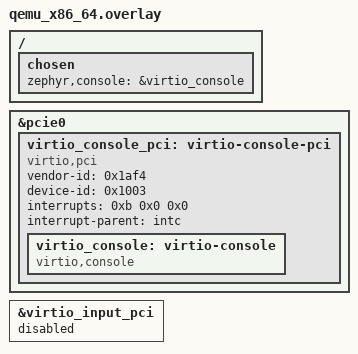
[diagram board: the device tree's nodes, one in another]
/*
 * Copyright (c) 2026 Process Mission
 *
 * SPDX-License-Identifier: Apache-2.0
 */

/ {
	chosen {
		zephyr,console = &virtio_console;
	};
};

&pcie0 {
	virtio_console_pci: virtio-console-pci {
		compatible = "virtio,pci";

		vendor-id = <0x1af4>;
		device-id = <0x1003>;

		interrupts = <0xb 0x0 0x0>;
		interrupt-parent = <&intc>;

		status = "okay";

		virtio_console: virtio-console {
			compatible = "virtio,console";
			status = "okay";
		};
	};
};

/* The board enables a virtio-input PCI device that this test does not provide
 * in QEMU. Disable it so the virtio-pci driver does not try to initialize a
 * device that is not present.
 */
&virtio_input_pci {
	status = "disabled";
};
